# CH32V307xx register map
Vendor: WCH Ltd.; File version: 1.0
Registers are 32-bit, read-write, reset 0x0 unless marked. A register's access mark holds for its fields unless they carry their own. Offsets are from the block's base; [hi:lo] are bit positions; lines under a group give offsets from that group; {n}, {i} and the like mark numbered series.

## USART1 — Universal synchronous asynchronous receiver transmitter
Base 0x40013800
Same registers: UART6 0x40001800, UART7 0x40001C00, UART8 0x40002000, USART2 0x40004400, USART3 0x40004800, UART4 0x40004C00, UART5 0x40005000
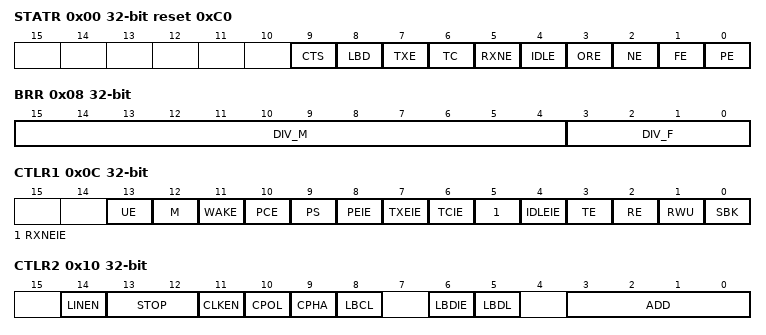
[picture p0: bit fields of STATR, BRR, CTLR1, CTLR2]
0x00 STATR access per field reset 0xC0 — Status register
  [9] CTS rw — CTS flag
  [8] LBD rw — LIN break detection flag
  [7] TXE ro — Transmit data register empty
  [6] TC rw — Transmission complete
  [5] RXNE rw — Read data register not empty
  [4] IDLE ro — IDLE line detected
  [3] ORE ro — Overrun error
  [2] NE ro — Noise error flag
  [1] FE ro — Framing error
  [0] PE ro — Parity error
0x04 DATAR — Data register
  [8:0] DR — Data value
0x08 BRR — Baud rate register
  [15:4] DIV_M — mantissa of USARTDIV
  [3:0] DIV_F — fraction of USARTDIV
0x0C CTLR1 — Control register 1
  [13] UE — USART enable
  [12] M — Word length
  [11] WAKE — Wakeup method
  [10] PCE — Parity control enable
  [9] PS — Parity selection
  [8] PEIE — PE interrupt enable
  [7] TXEIE — TXE interrupt enable
  [6] TCIE — Transmission complete interrupt enable
  [5] RXNEIE — RXNE interrupt enable
  [4] IDLEIE — IDLE interrupt enable
  [3] TE — Transmitter enable
  [2] RE — Receiver enable
  [1] RWU — Receiver wakeup
  [0] SBK — Send break
0x10 CTLR2 — Control register 2
  [14] LINEN — LIN mode enable
  [13:12] STOP — STOP bits
  [11] CLKEN — Clock enable
  [10] CPOL — Clock polarity
  [9] CPHA — Clock phase
  [8] LBCL — Last bit clock pulse
  [6] LBDIE — LIN break detection interrupt enable
  [5] LBDL — lin break detection length
  [3:0] ADD — Address of the USART node
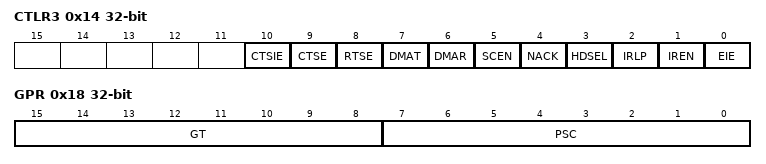
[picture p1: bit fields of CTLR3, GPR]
0x14 CTLR3 — Control register 3
  [10] CTSIE — CTS interrupt enable
  [9] CTSE — CTS enable
  [8] RTSE — RTS enable
  [7] DMAT — DMA enable transmitter
  [6] DMAR — DMA enable receiver
  [5] SCEN — Smartcard mode enable
  [4] NACK — Smartcard NACK enable
  [3] HDSEL — Half-duplex selection
  [2] IRLP — IrDA low-power
  [1] IREN — IrDA mode enable
  [0] EIE — Error interrupt enable
0x18 GPR — Guard time and prescaler register
  [15:8] GT — Guard time value
  [7:0] PSC — Prescaler value

## ADC1 — Analog to digital converter
Base 0x40012400
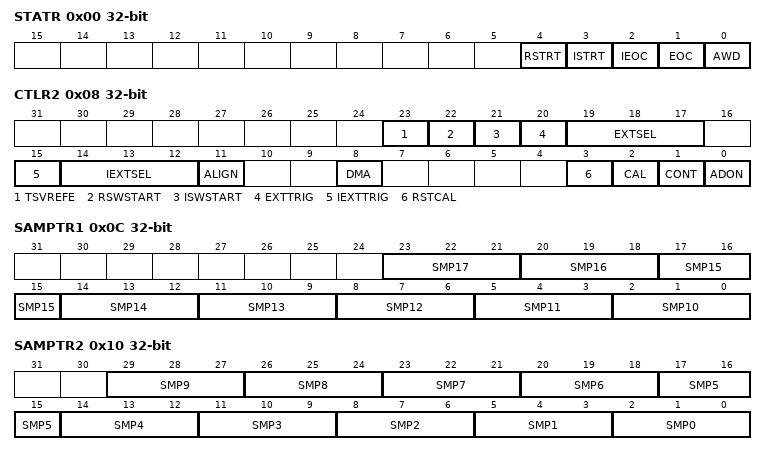
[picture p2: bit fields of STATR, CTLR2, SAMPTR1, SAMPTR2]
0x00 STATR — status register
  [4] RSTRT — Regular channel start flag
  [3] ISTRT — Injected channel start flag
  [2] IEOC — Injected channel end of conversion
  [1] EOC — Regular channel end of conversion
  [0] AWD — Analog watchdog flag
0x04 CTLR1 — control register 1/TKEY_V_CTLR
  [28:27] ADC_PGA
  [26] ADC_BUF_EN — TKEY_BUF_Enable
  [25] TKEY_ITUNE — TKEY_I enable
  [24] TKEY_EN — TKEY enable, including TKEY_F and TKEY_V
  [23] RAWDEN — Analog watchdog enable on regular channels
  [22] IAWDEN — Analog watchdog enable on injected channels
  [22] IAWDEN — Analog watchdog enable on injected channels
  [19:16] DUALMOD — Dual mode selection
  [15:13] DISCNUM — Discontinuous mode channel count
  [12] IDISCEN — Discontinuous mode on injected channels
  [11] RDISCEN — Discontinuous mode on regular channels
  [10] IAUTO — Automatic injected group conversion
  [9] AWDSGL — Enable the watchdog on a single channel in scan mode
  [8] SCAN — Scan mode enable
  [7] IEOCIE — Interrupt enable for injected channels
  [6] AWDIE — Analog watchdog interrupt enable
  [5] EOCIE — Interrupt enable for EOC
  [4:0] AWDCH — Analog watchdog channel select bits
0x08 CTLR2 — control register 2
  [23] TSVREFE — Temperature sensor and VREFINT enable
  [22] RSWSTART — Start conversion of regular channels
  [21] ISWSTART — Start conversion of injected channels
  [20] EXTTRIG — External trigger conversion mode for regular channels
  [19:17] EXTSEL — External event select for regular group
  [15] IEXTTRIG — External trigger conversion mode for injected channels
  [14:12] IEXTSEL — External event select for injected group
  [11] ALIGN — Data alignment
  [8] DMA — Direct memory access mode
  [3] RSTCAL — Reset calibration
  [2] CAL — A/D calibration
  [1] CONT — Continuous conversion
  [0] ADON — A/D converter ON / OFF
0x0C SAMPTR1 — sample time register 1
  [3n-28:3n-30] SMP{n} (n=10..17) — Channel {n} sample time selection
0x10 SAMPTR2 — sample time register 2
  [3n+2:3n] SMP{n} (n=0..9) — Channel {n} sample time selection
{0x10+4i} IOFR{i} (i=1..4) — injected channel data offset register x
  [11:0] IOFFSET{i} — Data offset for injected channel x
0x24 WDHTR — watchdog higher threshold register
  [11:0] HT — Analog watchdog higher threshold
0x28 WDLTR — watchdog lower threshold register
  [11:0] LT — Analog watchdog lower threshold
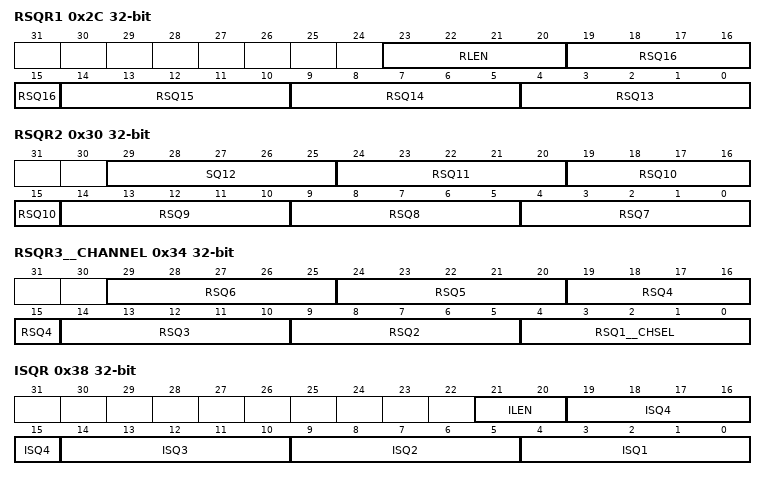
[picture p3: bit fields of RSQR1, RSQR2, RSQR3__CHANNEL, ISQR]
0x2C RSQR1 — regular sequence register 1
  [23:20] RLEN — Regular channel sequence length
  [5n-61:5n-65] RSQ{n} (n=13..16) — {n}th conversion in regular sequence
0x30 RSQR2 — regular sequence register 2
  [29:25] SQ12 — 12th conversion in regular sequence
  [5n-31:5n-35] RSQ{n} (n=7..11) — {n}th conversion in regular sequence
0x34 RSQR3__CHANNEL — regular sequence register 3;TKEY_V_CHANNEL
  [29:25] RSQ6 — 6th conversion in regular sequence
  [24:20] RSQ5 — 5th conversion in regular sequence
  [19:15] RSQ4 — 4th conversion in regular sequence
  [14:10] RSQ3 — 3rd conversion in regular sequence
  [9:5] RSQ2 — 2nd conversion in regular sequence
  [4:0] RSQ1__CHSEL — 1st conversion in regular sequence;TKDY_V channel select
0x38 ISQR — injected sequence register
  [21:20] ILEN — Injected sequence length
  [19:15] ISQ4 — 4th conversion in injected sequence
  [14:10] ISQ3 — 3rd conversion in injected sequence
  [9:5] ISQ2 — 2nd conversion in injected sequence
  [4:0] ISQ1 — 1st conversion in injected sequence
{0x38+4i} IDATAR{i} ro (i=1..4) — injected data register x
  [15:0] IDATA — Injected data
0x4C RDATAR__SDR ro — regular data register;TKEY_V status register
  [15:0] RDATA — Regular data
